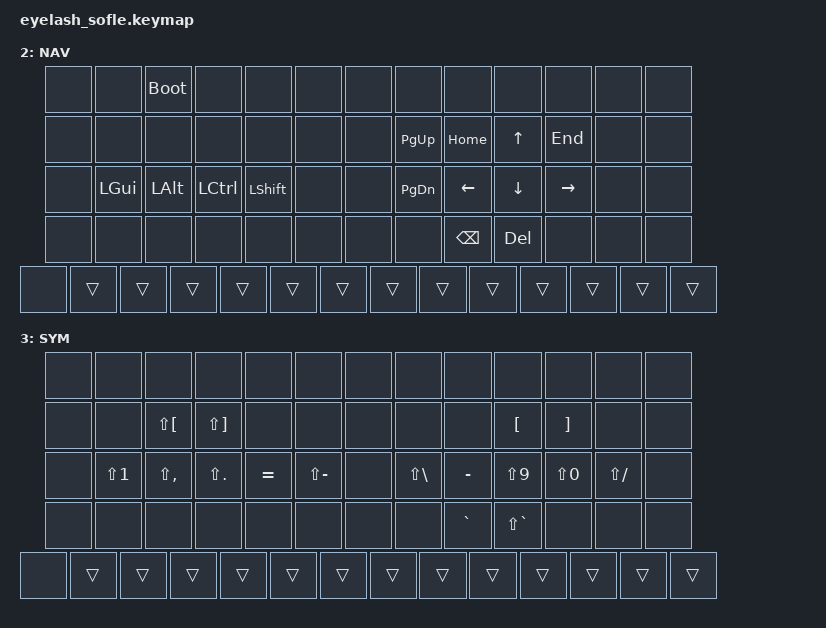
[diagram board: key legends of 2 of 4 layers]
#define ZMK_POINTING_DEFAULT_MOVE_VAL 1200  // 600
#define ZMK_POINTING_DEFAULT_SCRL_VAL 25   // 10

#include <input/processors.dtsi>
#include <zephyr/dt-bindings/input/input-event-codes.h>
#include <behaviors.dtsi>
#include <dt-bindings/zmk/bt.h>
#include <dt-bindings/zmk/ext_power.h>
#include <dt-bindings/zmk/keys.h>
#include <dt-bindings/zmk/pointing.h>
#include <dt-bindings/zmk/rgb.h>
#include <dt-bindings/zmk/outputs.h>

&mmv_input_listener { input-processors = <&zip_xy_scaler 2 1>; };

&msc_input_listener { input-processors = <&zip_scroll_scaler 2 1>; };

&msc {
    acceleration-exponent = <1>;      // 0
    time-to-max-speed-ms = <100>;       // 300
    delay-ms = <0>;                   // 0
};

&mmv {
    time-to-max-speed-ms = <500>;
    acceleration-exponent = <1>;
    trigger-period-ms = <16>;
};


/ {
    behaviors {
        hmls: home_row_mod_lefts {
            compatible = "zmk,behavior-hold-tap";
            #binding-cells = <2>;
            flavor = "balanced";
            tapping-term-ms = <250>;
            bindings = <&kp>, <&kp>;
            hold-trigger-key-positions = <59 60 61 62 63 7 8 9 10 11 12 20 21 22 23 24 25 33 34 35 36 37 38 46 47 48 49 10 11 12 23 24 25 36 37 38 49 50 51 63>;
            hold-trigger-on-release;
        };
        hmrs: home_row_mod_rights {
            compatible = "zmk,behavior-hold-tap";
            #binding-cells = <2>;
            flavor = "balanced";
            tapping-term-ms = <250>;
            bindings = <&kp>, <&kp>;
            hold-trigger-key-positions = <0 1 2 3 4 5 13 14 15 16 17 18 26 27 28 29 30 31 39 40 41 42 43 44 53 54 55 56 57>;
            hold-trigger-on-release;
        };
        hml: home_row_mod_left {
            compatible = "zmk,behavior-hold-tap";
            #binding-cells = <2>;
            flavor = "balanced";
            require-prior-idle-ms = <100>;
            tapping-term-ms = <250>;
            bindings = <&kp>, <&kp>;
            hold-trigger-key-positions = <59 60 61 62 63 7 8 9 10 11 12 20 21 22 23 24 25 33 34 35 36 37 38 46 47 48 49 10 11 12 23 24 25 36 37 38 49 50 51 63>;
            hold-trigger-on-release;
        };
        hmr: home_row_mod_right {
            compatible = "zmk,behavior-hold-tap";
            #binding-cells = <2>;
            flavor = "balanced";
            require-prior-idle-ms = <100>;
            tapping-term-ms = <250>;
            bindings = <&kp>, <&kp>;
            hold-trigger-key-positions = <0 1 2 3 4 5 13 14 15 16 17 18 26 27 28 29 30 31 39 40 41 42 43 44 53 54 55 56 57>;
            hold-trigger-on-release;
        };
        hmlw: home_row_mod_leftw {
            compatible = "zmk,behavior-hold-tap";
            #binding-cells = <2>;
            flavor = "balanced";
            require-prior-idle-ms = <200>;
            tapping-term-ms = <250>;
            bindings = <&kp>, <&kp>;
            hold-trigger-key-positions = <59 60 61 62 63 7 8 9 10 11 12 20 21 22 23 24 25 33 34 35 36 37 38 46 47 48 49 10 11 12 23 24 25 36 37 38 49 50 51 63>;
            hold-trigger-on-release;
        };
        hmrw: home_row_mod_rightw {
            compatible = "zmk,behavior-hold-tap";
            #binding-cells = <2>;
            flavor = "balanced";
            require-prior-idle-ms = <200>;
            tapping-term-ms = <250>;
            bindings = <&kp>, <&kp>;
            hold-trigger-key-positions = <0 1 2 3 4 5 13 14 15 16 17 18 26 27 28 29 30 31 39 40 41 42 43 44 53 54 55 56 57>;
            hold-trigger-on-release;
        };                
    };    

    scroll_encoder: scroll_encoder {
        compatible = "zmk,behavior-sensor-rotate";
        #sensor-binding-cells = <0>;
        bindings = <&msc SCRL_DOWN>, <&msc SCRL_UP>;
        tap-ms = <100>;
    };

    keymap {
        compatible = "zmk,keymap";

        layer0 {
            bindings = <
&kp ESC     &kp N1     &kp N2        &kp N3        &kp N4  &kp N5                &none    &none      &kp LNLCK          &none          &none           &none      &none
&kp TAB     &kp Q      &kp W         &kp E         &kp R   &kp T                 &none    &none      &kp KP_N7      &kp KP_N8      &kp KP_N9            &none       &none
&kp BSPC    &hmlw LGUI A  &hml LALT S  &hml LCTRL D  &hmls LSHFT F   &kp G       &none    &none      &kp KP_N4      &kp KP_N5      &kp KP_N6 &none    &none
&kp LSHFT   &kp Z      &kp X         &kp C         &kp V   &kp B                 &none    &none      &kp KP_N1      &kp KP_N2  &kp KP_N3          &none    &none
&none  &kp LCTRL  &kp LGUI  &mo 1  &kp SPACE &mo 2            &none         &mo 3 &kp KP_N0  &none      &none  &none
            >;

            sensor-bindings = <&inc_dec_kp C_VOLUME_UP C_VOL_DN>;
            display-name = "BASE";
        };

        layer_1 {
            bindings = <
&kp GRAVE   &none &bootloader &none &none &none      &none       &none &none &none &none &none &none
&studio_unlock &bt BT_CLR &bt BT_SEL 0 &bt BT_SEL 1 &bt BT_SEL 2 &none         &none       &none &kp F1 &kp F2 &kp F3 &kp F4 &none
&none &kp LGUI &kp LALT &kp LCTRL &kp LSHFT &none    &none       &none &kp F5 &kp F6 &kp F7 &kp F8 &none
&none &none &none &none &none &none                  &none       &none &kp F9 &kp F10 &kp F11 &kp F12 &none
&none  &trans &trans &trans  &trans           &trans             &trans  &trans  &trans &trans &trans &trans
            >;

            display-name = "FN";
            sensor-bindings = <&scroll_encoder>;
        };

        layer_2 {
            bindings = <
&none &none &bootloader &none &none &none            &none       &none &none &none &none &none &none
&none &none &none &none &none &none                  &none       &kp PG_UP &kp HOME &kp UP &kp END &none &none
&none &kp LGUI &kp LALT &kp LCTRL &kp LSHFT &none    &none       &kp PG_DN &kp LEFT &kp DOWN &kp RIGHT &none &none
&none &none &none &none &none &none                  &none       &none &kp BSPC &kp DELETE &none &none &none
&none  &trans &trans &trans  &trans           &trans             &trans  &trans  &trans &trans &trans &trans     &trans     &trans
            >;

            display-name = "NAV";
            sensor-bindings = <&scroll_encoder>;
        };

        layer_3 {
            bindings = <
&none &none &none &none &none &none      &none       &none &none &none &none &none &none
&none &none &kp LS(LBKT) &kp LS(RBKT) &none &none         &none       &none &none &kp LBKT &kp RBKT &none &none
&none &kp LS(N1) &kp LS(COMMA) &kp LS(DOT) &kp EQUAL &kp LS(MINUS)    &none       &kp LS(BSLH) &kp MINUS &kp LS(N9) &kp LS(N0) &kp LS(SLASH) &none
&none &none &none &none &none &none                  &none       &none &kp GRAVE &kp LS(GRAVE) &none &none &none
&none  &trans &trans &trans  &trans           &trans             &trans  &trans  &trans &trans &trans &trans     &trans     &trans
            >;

            display-name = "SYM";
            sensor-bindings = <&scroll_encoder>;
        };
    };
};
